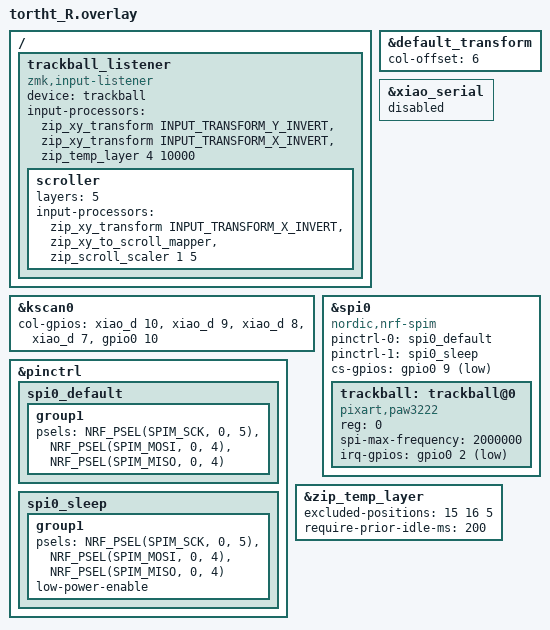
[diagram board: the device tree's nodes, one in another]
#include "tortht.dtsi"
#include <input/processors.dtsi>
#include <dt-bindings/zmk/input_transform.h>
#include <zephyr/dt-bindings/input/input-event-codes.h>

&default_transform {
    col-offset = <6>;
};

&kscan0 {
        col-gpios
            = <&xiao_d 10 GPIO_ACTIVE_HIGH>
            , <&xiao_d 9 GPIO_ACTIVE_HIGH> 
            , <&xiao_d 8 GPIO_ACTIVE_HIGH> 
            , <&xiao_d 7 GPIO_ACTIVE_HIGH> 
            , <&gpio0 10 GPIO_ACTIVE_HIGH>
            ;
};

/ {
    trackball_listener: trackball_listener {
        compatible = "zmk,input-listener";
        device = <&trackball>;

    };
};

&pinctrl {
    spi0_default: spi0_default {
        group1 {
            psels = <NRF_PSEL(SPIM_SCK, 0, 5)>,
                <NRF_PSEL(SPIM_MOSI, 0, 4)>,
                <NRF_PSEL(SPIM_MISO, 0, 4)>;
        };
    };

    spi0_sleep: spi0_sleep {
        group1 {
            psels = <NRF_PSEL(SPIM_SCK, 0, 5)>,
                <NRF_PSEL(SPIM_MOSI, 0, 4)>,
                <NRF_PSEL(SPIM_MISO, 0, 4)>;
            low-power-enable;
        };
    };
};

&xiao_serial { status = "disabled"; };

&spi0 {
    status = "okay";
    compatible = "nordic,nrf-spim";
    pinctrl-0 = <&spi0_default>;
    pinctrl-1 = <&spi0_sleep>;
    pinctrl-names = "default", "sleep";
    cs-gpios = <&gpio0 9 GPIO_ACTIVE_LOW>;

    trackball: trackball@0 {
        status = "okay";
        compatible = "pixart,paw3222";
        reg = <0>;
        spi-max-frequency = <2000000>;
        irq-gpios = <&gpio0 2 GPIO_ACTIVE_LOW>;
    };
};

&trackball_listener {
    status = "okay";
    device = <&trackball>;
        input-processors = 
            //<&zip_xy_transform INPUT_TRANSFORM_XY_SWAP>,        //X幉偲Y幉偺擖傟懼偊
            <&zip_xy_transform INPUT_TRANSFORM_Y_INVERT>,       //Y幉斀揮
            <&zip_xy_transform INPUT_TRANSFORM_X_INVERT>,       //X幉斀揮
            <&zip_temp_layer 4 10000>;                            //僆乕僩儅僂僗儗僀儎乕偺慖戰
    scroller {
        layers = <5>;
        input-processors = 
           //<&zip_xy_transform INPUT_TRANSFORM_XY_SWAP>,        //X幉偲Y幉偺擖傟懼偊
            <&zip_xy_transform INPUT_TRANSFORM_X_INVERT>,       //X幉斀揮
           // <&zip_xy_transform INPUT_TRANSFORM_Y_INVERT>,       //Y幉斀揮
            <&zip_xy_to_scroll_mapper>,                         //僗僋儘乕儖儌乕僪偵曄峏
            <&zip_scroll_scaler 1 5>;                           //僗僋儘乕儖検傪1/4攞
    };
};

// / {
//   /omit-if-no-ref/ zip_temp_layer: zip_temp_layer {
//     compatible = "zmk,input-processor-temp-layer";
//     #input-processor-cells = <2>;
//     require-prior-idle-ms = <350>; /* 僉乕墴壓屻丄壗ms僆乕僩儅僂僗儗僀儎偵擖傜側偄傛偆偵偡傞偐丄岆敋杊巭 */
//   };
// };

&zip_temp_layer {
    excluded-positions = <
        15 // h
        16 // j
        5  // u
//        10 // a
//        20 // z
//        21 // x
//        22 // c
    >;
    require-prior-idle-ms = <200>;
};


